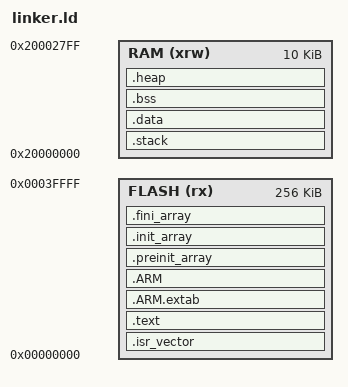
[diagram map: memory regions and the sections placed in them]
/*
OUTPUT_FORMAT("elf32-littlearm", "elf32-bigarm", "elf32-littlearm")
OUTPUT_ARCH(arm)
*/

/* Entry Point */
ENTRY(Reset_Handler)

/* Specify the memory areas */
MEMORY
{
FLASH (rx)       : ORIGIN = 0x00000000, LENGTH = 256K
RAM   (xrw)      : ORIGIN = 0x20000000, LENGTH = 10K
}

/* Stack Size */
/* STACK_SIZE = 3072; */
STACK_SIZE = 2048;

/* Heap Size */
HEAP_SIZE = 0;

/* Define output sections */
SECTIONS
{
  /* The startup code goes first into FLASH */
  .isr_vector :
  {
    . = ALIGN(4);
    KEEP(*(.isr_vector)) /* Startup code */
    . = ALIGN(4);
  } >FLASH

  /* The program code and other data goes into FLASH */
  .text :
  {
    . = ALIGN(4);
    *(.text)           /* .text sections (code) */
    *(.text*)          /* .text* sections (code) */
    *(.glue_7)         /* glue arm to thumb code */
    *(.glue_7t)        /* glue thumb to arm code */
    *(.eh_frame)
    *(.rodata)         /* .rodata sections (constants, strings, etc.) */
    *(.rodata*)        /* .rodata* sections (constants, strings, etc.) */

    KEEP (*(.init))
    KEEP (*(.fini))

    . = ALIGN(4);
  } >FLASH

  .ARM.extab   : { *(.ARM.extab* .gnu.linkonce.armextab.*) } >FLASH
  .ARM : {
    __exidx_start = .;
    *(.ARM.exidx*)
    __exidx_end = .;
  } >FLASH

  .preinit_array     :
  {
    PROVIDE_HIDDEN (__preinit_array_start = .);
    KEEP (*(.preinit_array*))
    PROVIDE_HIDDEN (__preinit_array_end = .);
  } >FLASH
  .init_array :
  {
    PROVIDE_HIDDEN (__init_array_start = .);
    KEEP (*(SORT(.init_array.*)))
    KEEP (*(.init_array*))
    PROVIDE_HIDDEN (__init_array_end = .);
  } >FLASH
  .fini_array :
  {
    PROVIDE_HIDDEN (__fini_array_start = .);
    KEEP (*(SORT(.fini_array.*)))
    KEEP (*(.fini_array*))
    PROVIDE_HIDDEN (__fini_array_end = .);
  } >FLASH

  _etext = .;        /* define a global symbols at end of code */


  .stack :
  {
    __stack_start__ = .;
    . = . + STACK_SIZE;
    . = ALIGN(4);
    *(.stack)
    __stack_end__ = .;
  } >RAM


  /* Initialized data sections goes into RAM, load LMA copy after code */
  .data : AT (_etext)
  {
    /* used by the startup to initialize data */
    _sidata = LOADADDR(.data);
    _sdata = .;        /* create a global symbol at data start */
    *(.data)           /* .data sections */
    *(.data*)          /* .data* sections */
    . = ALIGN(4);
    _edata = .;        /* define a global symbol at data end */
  } >RAM


  /* Uninitialized data section */
  .bss :
  {
    /* This is used by the startup in order to initialize the .bss secion */
    _sbss = .;         /* define a global symbol at bss start */
    __bss_start__ = _sbss;
    *(.bss)
    *(.bss*)
    *(COMMON)
    . = ALIGN(4);
    _ebss = .;         /* define a global symbol at bss end */
    __bss_end__ = _ebss;
  } >RAM

  .heap :
  {
    __heap_start__ = .;
    . = . + HEAP_SIZE;
    . = ALIGN(4);
    *(.heap)
    __heap_end__ = .;
  } >RAM


  /* Remove information from the standard libraries */
  /DISCARD/ :
  {
    libc.a ( * )
    libm.a ( * )
    libgcc.a ( * )
  }

  .ARM.attributes 0 : { *(.ARM.attributes) }
}
